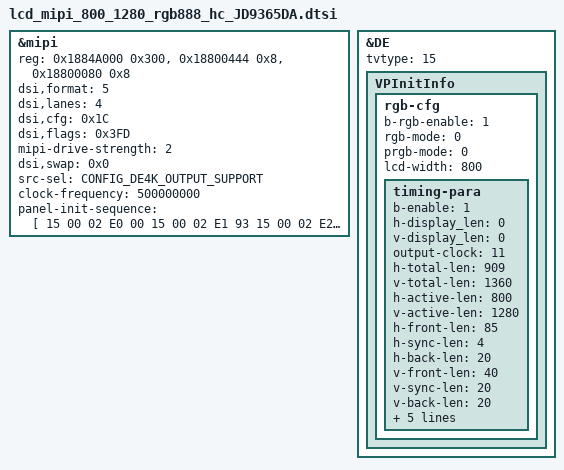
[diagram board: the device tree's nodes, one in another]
&mipi {
	reg = <0x1884A000 0x300>, <0x18800444 0x8>,<0x18800080 0x8>;

	/*
	 * MIPI_COLOR_RGB565_0	=	0
	 * MIPI_COLOR_RGB565_1	=	1
	 * MIPI_COLOR_RGB565_2	=	2
	 * MIPI_COLOR_RGB666_0	=	3
	 * MIPI_COLOR_RGB666_1	=	4
	 * MIPI_COLOR_RGB888	=	5
	 */
	dsi,format =<5>;

	dsi,lanes = <4>;

	/*
	 * bit 6:5 :Generic interface read-back Virtual Channel identification.
	 * bit 4 :Enables CRC reception and error reporting.
	 * bit 3 :Enables ECC reception, error correction and reporting
	 * bit 2 :MIPI_Bus_Turn_request.
	 * bit 1 :Enables EOTp reception.
	 * bit 0 :Enables EOTp transmission.
	 */
	dsi,cfg = <0x1C>;

	/* If there is no "dsi,flags", "dsi,flags" = <0x3FD>;
	 * bit 11: Enables the request for an acknowledge response at the end of a fram
	 * bit 10: Enables the transmission of null packets in the HACT period
	 * bit 9:  Enables the transmission of multi video packets in the HACT period
	 * bit 8:  Enables return to Low Power inside HFP period when timing allows.
	 * bit 7:  Enables return to Low Power inside HBP period when timing allows
	 * bit 6:  Enables return to Low Power inside VACT period when timing allows.
	 * bit 5:  Enables return to Low Power inside VFP period when timing allows
	 * bit 4:  Enables return to Low Power inside VBP period when timing allows
	 * bit 3:  Enables return to Low Power inside VSA period when timing allows
	 * bit 2:1 Selects video mode transmission type. 0: Non-burst with Sync pulses; 1: Non-burst with Sync events; 2-3: Burst with Sync pulses.
	 * bit 0:  Enables DPI Video mode transmission.
	 */
	dsi,flags = <0x3FD>;

	/*
	 * 0: MIPI_DRIVE_STRENGTH_MIDIMUN,
	 * 1: MIPI_DRIVE_STRENGTH_MIDDLE,
	 * 2: MIPI_DRIVE_STRENGTH_BIGGER, default
	 * 3: MIPI_DRIVE_STRENGTH_MAXIMUM,
	*/
	mipi-drive-strength = <2>;

	/*
	 * bit 4 : MIPI_DSI_DATA3_LANE_NP_SWAP
	 * bit 3 : MIPI_DSI_DATA2_LANE_NP_SWAP
	 * bit 2 : MIPI_DSI_DATA1_LANE_NP_SWAP
	 * bit 1 : MIPI_DSI_DATA0_LANE_NP_SWAP
	 * bit 0 : MIPI_DSI_CLOCK_LANE_NP_SWAP
	 */

	dsi,swap = <0x0>;
	/*
	 * 0: E_SRC_SEL_FXDE = 0
	 * 1: E_SRC_SEL_4KDE
	 * 2: E_SRC_SEL_HDMI_RX
	 */
	src-sel = <CONFIG_DE4K_OUTPUT_SUPPORT>;
	clock-frequency = <500000000>;
	//status = "okay";
};

&DE {
	tvtype = <15>;
	VPInitInfo {
		rgb-cfg{
			b-rgb-enable = <1>;
			/*
			 * 0: MODE_PRGB
			 * 1: MODE_SRGB
			 */
			rgb-mode = <0>;
			/*
			 * 0: MODE_PRGB_888_10bit
			 * 1: MODE_PRGB_666
			 */
			prgb-mode = <0>;
			lcd-width = <800>;
			timing-para {
				/* bool type, 0 or 1*/
				b-enable = <1>;

				h-display_len = <0>;
				v-display_len = <0>;

				/*
				 * VPO_RGB_CLOCK_27M = 1,
				 * VPO_RGB_CLOCK_33M = 2,
				 * VPO_RGB_CLOCK_49M = 3,
				 * VPO_RGB_CLOCK_66M = 4,
				 * VPO_RGB_CLOCK_74M = 5,
				 * VPO_RGB_CLOCK_85M = 6,
				 * VPO_RGB_CLOCK_108M = 7,
				 * VPO_RGB_CLOCK_6_6M = 8,
				 * VPO_RGB_CLOCK_9M = 9,
				 * VPO_RGB_CLOCK_39_6M = 10,
				 * VPO_RGB_CLOCK_74_25M = 11,
				 * VPO_RGB_CLOCK_148_5M = 12,
				 * VPO_RGB_CLOCK_54M = 13,
				 * VPO_RGB_CLOCK_132M = 14,//H1600
				 * VPO_RGB_CLOCK_297M = 15,//H1600 only De4k
				 * VPO_RGB_CLOCK_DPLL = 0xFF,//H1600
				*/
				output-clock = <11>;

				h-total-len = <909>;
				v-total-len = <1360>;

				h-active-len = <800>;
				v-active-len = <1280>;

				h-front-len = <85>;
				h-sync-len = <4>;
				h-back-len = <20>;

				v-front-len = <40>;
				v-sync-len = <20>;
				v-back-len = <20>;

				/* bool type, 0 or 1*/
				h-sync-level = <0>;
				/* bool type, 0 or 1*/
				v-sync-level = <0>;

				/* bool type, 0 or 1*/
				active-polarity = <1>;
				frame-rate = <60000>;

				/*
				31	De_dig_pll_en
				25:16	DE_DIG_PLL_M_ctrl
				13:8	DE_DIG_PLL_N_ctrl
				5:0	DE_DIG_PLL_L_ctrl
				de_digpll_clock = 24 *(M+1)/((N+1)*(L+1))
				*/
				dpll-clock-reg-value = <0x0>;
			};
		};
	};
};

&mipi{
	panel-init-sequence = [
		15 00 02 E0 00
		15 00 02 E1 93
		15 00 02 E2 65
		15 00 02 E3 F8
		15 00 02 80 03
		15 00 02 E0 01
		15 00 02 00 00
		15 00 02 01 38
		15 00 02 0C 74
		15 00 02 17 00
		15 00 02 18 AF
		15 00 02 19 00
		15 00 02 1A 00
		15 00 02 1B AF
		15 00 02 1C 00
		15 00 02 35 26
		15 00 02 37 09
		15 00 02 38 04
		15 00 02 39 00
		15 00 02 3A 01
		15 00 02 3C 78
		15 00 02 3D FF
		15 00 02 3E FF
		15 00 02 3F 7F
		15 00 02 40 06
		15 00 02 41 A0
		15 00 02 42 81
		15 00 02 43 14
		15 00 02 44 23
		15 00 02 45 28
		15 00 02 55 02
		15 00 02 57 69
		15 00 02 59 0A
		15 00 02 5A 2A
		15 00 02 5B 17
		15 00 02 5D 7F
		15 00 02 5E 6A
		15 00 02 5F 5B
		15 00 02 60 4F
		15 00 02 61 4A
		15 00 02 62 3D
		15 00 02 63 41
		15 00 02 64 2A
		15 00 02 65 44
		15 00 02 66 43
		15 00 02 67 44
		15 00 02 68 62
		15 00 02 69 52
		15 00 02 6A 59
		15 00 02 6B 4C
		15 00 02 6C 48
		15 00 02 6D 3A
		15 00 02 6E 26
		15 00 02 6F 00
		15 00 02 70 7F
		15 00 02 71 6A
		15 00 02 72 5B
		15 00 02 73 4F
		15 00 02 74 4A
		15 00 02 75 3D
		15 00 02 76 41
		15 00 02 77 2A
		15 00 02 78 44
		15 00 02 79 43
		15 00 02 7A 44
		15 00 02 7B 62
		15 00 02 7C 52
		15 00 02 7D 59
		15 00 02 7E 4C
		15 00 02 7F 48
		15 00 02 80 3A
		15 00 02 81 26
		15 00 02 82 00
		15 00 02 E0 02
		15 00 02 00 42
		15 00 02 01 42
		15 00 02 02 40
		15 00 02 03 40
		15 00 02 04 5E
		15 00 02 05 5E
		15 00 02 06 5F
		15 00 02 07 5F
		15 00 02 08 5F
		15 00 02 09 57
		15 00 02 0A 57
		15 00 02 0B 77
		15 00 02 0C 77
		15 00 02 0D 47
		15 00 02 0E 47
		15 00 02 0F 45
		15 00 02 10 45
		15 00 02 11 4B
		15 00 02 12 4B
		15 00 02 13 49
		15 00 02 14 49
		15 00 02 15 5F
		15 00 02 16 41
		15 00 02 17 41
		15 00 02 18 40
		15 00 02 19 40
		15 00 02 1A 5E
		15 00 02 1B 5E
		15 00 02 1C 5F
		15 00 02 1D 5F
		15 00 02 1E 5F
		15 00 02 1F 57
		15 00 02 20 57
		15 00 02 21 77
		15 00 02 22 77
		15 00 02 23 46
		15 00 02 24 46
		15 00 02 25 44
		15 00 02 26 44
		15 00 02 27 4A
		15 00 02 28 4A
		15 00 02 29 48
		15 00 02 2A 48
		15 00 02 2B 5F
		15 00 02 2C 01
		15 00 02 2D 01
		15 00 02 2E 00
		15 00 02 2F 00
		15 00 02 30 1F
		15 00 02 31 1F
		15 00 02 32 1E
		15 00 02 33 1E
		15 00 02 34 1F
		15 00 02 35 17
		15 00 02 36 17
		15 00 02 37 37
		15 00 02 38 37
		15 00 02 39 08
		15 00 02 3A 08
		15 00 02 3B 0A
		15 00 02 3C 0A
		15 00 02 3D 04
		15 00 02 3E 04
		15 00 02 3F 06
		15 00 02 40 06
		15 00 02 41 1F
		15 00 02 42 02
		15 00 02 43 02
		15 00 02 44 00
		15 00 02 45 00
		15 00 02 46 1F
		15 00 02 47 1F
		15 00 02 48 1E
		15 00 02 49 1E
		15 00 02 4A 1F
		15 00 02 4B 17
		15 00 02 4C 17
		15 00 02 4D 37
		15 00 02 4E 37
		15 00 02 4F 09
		15 00 02 50 09
		15 00 02 51 0B
		15 00 02 52 0B
		15 00 02 53 05
		15 00 02 54 05
		15 00 02 55 07
		15 00 02 56 07
		15 00 02 57 1F
		15 00 02 58 40
		15 00 02 5B 30
		15 00 02 5C 16
		15 00 02 5D 34
		15 00 02 5E 05
		15 00 02 5F 02
		15 00 02 63 00
		15 00 02 64 6A
		15 00 02 67 73
		15 00 02 68 1D
		15 00 02 69 08
		15 00 02 6A 6A
		15 00 02 6B 08
		15 00 02 6C 00
		15 00 02 6D 00
		15 00 02 6E 00
		15 00 02 6F 88
		15 00 02 75 FF
		15 00 02 77 DD
		15 00 02 78 3F
		15 00 02 79 15
		15 00 02 7A 17
		15 00 02 7D 14
		15 00 02 7E 82
		15 00 02 E0 04
		15 00 02 00 0E
		15 00 02 02 B3
		15 00 02 09 61
		15 00 02 0E 48
		15 00 02 E0 00
		15 00 02 E6 02
		15 00 02 E7 0C
		05 c8 01 11
		15 00 02 E0 00
		05 64 01 29
		15 00 02 35 00
	];
};
